# Cortex_M33 register map
Vendor: ARM Ltd.; File version: 1.3
CPU: CM33 r0p0, little endian, MPU, no FPU, vendor SysTick, 8 interrupt priority bits
Registers are 32-bit, read-write, no defined reset value unless marked. A register's access mark holds for its fields unless they carry their own. Offsets are from the block's base; [hi:lo] are bit positions; {n}, {i} and the like mark numbered series; 'fields as' and 'values as' point back to an identical list.

## ICB — Interrupt Control Registers
Base 0xE000E004
0x00 ICTR ro
  [3:0] INTLINESNUM
0x04 ACTLR
0x08 CPPWR
  [23] SUS11, [22] SU11, [21] SUS10, [20] SU10, [n] SUS{n} (n=0..7), [n] SU{n} (n=0..7)

## MPU — Memory protection Unit Control Registers
Base 0xE000ED90
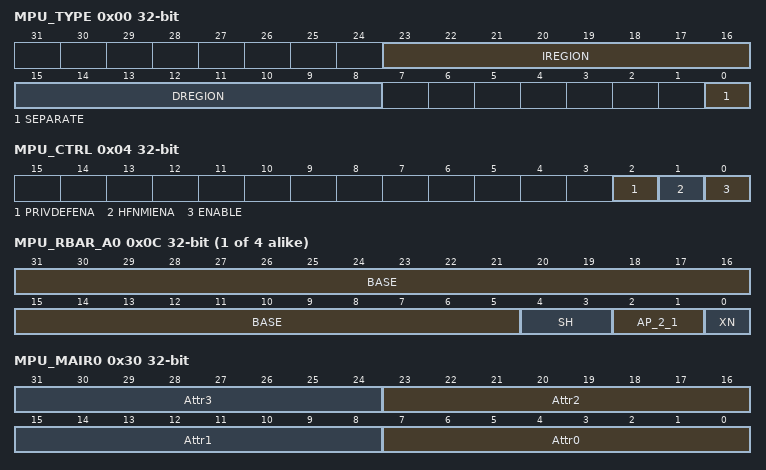
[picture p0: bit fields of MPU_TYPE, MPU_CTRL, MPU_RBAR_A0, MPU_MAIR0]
0x00 MPU_TYPE ro — MPU Type Register S
  [23:16] IREGION
  [15:8] DREGION
  [0] SEPARATE
    0=Uniform; 1=Separate
0x04 MPU_CTRL — MPU Control Register S
  [2] PRIVDEFENA, [1] HFNMIENA, [0] ENABLE
0x08 MPU_RNR — MPU Region Number Register S
  [7:0] REGION
0x0C MPU_RBAR_A{i} (i=0..3) — MPU_RBAR_A{i}_S
  [31:5] BASE, [4:3] SH, [2:1] AP_2_1, [0] XN
0x30 MPU_MAIR0 — MPU_MAIR0_S
  [8n+7:8n] Attr{n} (n=0..3)
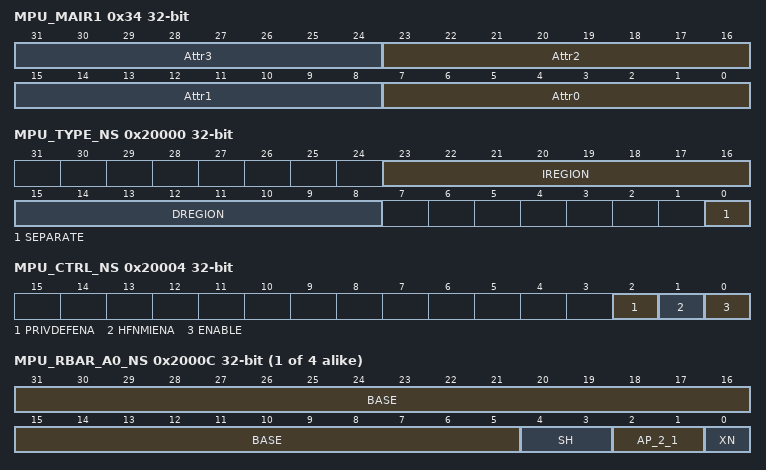
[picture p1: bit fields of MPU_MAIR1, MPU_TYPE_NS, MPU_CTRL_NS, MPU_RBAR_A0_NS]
0x34 MPU_MAIR1 — MPU_MAIR1_S
  [8n+7:8n] Attr{n} (n=0..3)
0x20000 MPU_TYPE_NS ro — MPU Type Register NS
  fields as MPU_TYPE
0x20004 MPU_CTRL_NS — MPU Control Register NS
  [2] PRIVDEFENA, [1] HFNMIENA, [0] ENABLE
0x20008 MPU_RNR_NS — MPU Region Number Register NS
  [7:0] REGION
0x2000C MPU_RBAR_A{i}_NS (i=0..3)
  [31:5] BASE, [4:3] SH, [2:1] AP_2_1, [0] XN
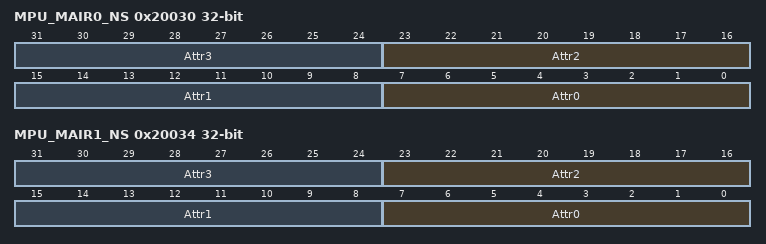
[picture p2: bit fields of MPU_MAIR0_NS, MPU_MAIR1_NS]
0x20030 MPU_MAIR0_NS
  [8n+7:8n] Attr{n} (n=0..3)
0x20034 MPU_MAIR1_NS
  [8n+7:8n] Attr{n} (n=0..3)

## NVIC — Nested Vectored Interrupt Controller registers
Base 0xE000E004
0x00 ICTR ro — Interrupt Controller Type Register
  [3:0] INTLINESNUM
{0xFC+4i} NVIC_ISER{i} reset 0x0 (i=0..15) — Interrupt Set-Enable Register
  [31:0] SETENA
{0x17C+4i} NVIC_ICER{i} reset 0x0 (i=0..15) — Interrupt Clear-Enable Register
  [31:0] CLRENA
{0x1FC+4i} NVIC_ISPR{i} reset 0x0 (i=0..15) — Interrupt Set-Pending Register
  [31:0] SETPEND
{0x27C+4i} NVIC_ICPR{i} reset 0x0 (i=0..15) — Interrupt Clear-Pending Register
  [31:0] CLRPEND
{0x2FC+4i} NVIC_IABR{i} reset 0x0 (i=0..15) — Interrupt Active Bit Register
  [31:0] ACTIVE
{0x37C+4i} ITNS{i} reset 0x0 (i=0..15) — Interrupt Target Non-secure Registers
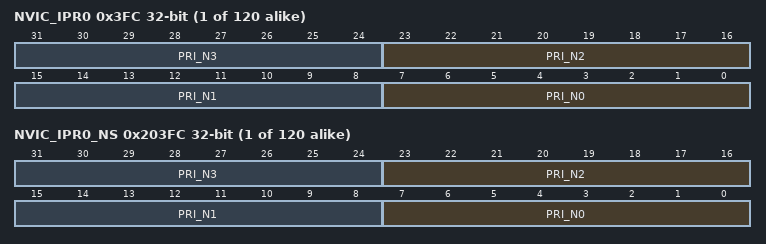
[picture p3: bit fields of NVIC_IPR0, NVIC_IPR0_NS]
{0x3FC+4i} NVIC_IPR{i} (i=0..119)
  [8n+7:8n] PRI_N{n} (n=0..3)
0x20000 ICTR_NS ro — Interrupt Controller Type Register NS
  [3:0] INTLINESNUM
{0x200FC+4i} NVIC_ISER{i}_NS reset 0x0 (i=0..15) — Interrupt Set-Enable Register
  [31:0] SETENA
{0x2017C+4i} NVIC_ICER{i}_NS reset 0x0 (i=0..15) — Interrupt Clear-Enable Register
  [31:0] CLRENA
{0x201FC+4i} NVIC_ISPR{i}_NS reset 0x0 (i=0..15) — Interrupt Set-Pending Register
  [31:0] SETPEND
{0x2027C+4i} NVIC_ICPR{i}_NS reset 0x0 (i=0..15) — Interrupt Clear-Pending Register
  [31:0] CLRPEND
{0x202FC+4i} NVIC_IABR{i}_NS reset 0x0 (i=0..15) — Interrupt Active Bit Register
  [31:0] ACTIVE
{0x203FC+4i} NVIC_IPR{i}_NS (i=0..119)
  [8n+7:8n] PRI_N{n} (n=0..3)

## SAU — Security Attribute Unit
Base 0xE000EDD0
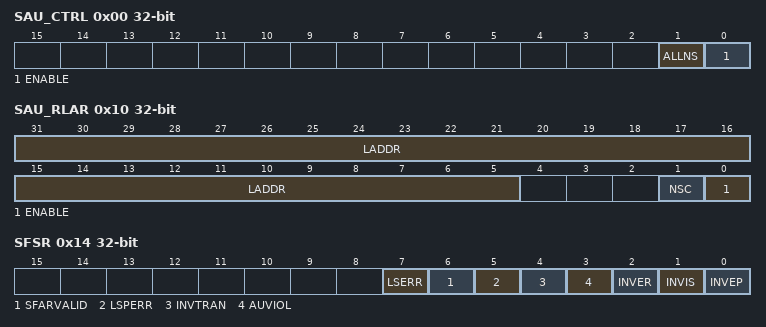
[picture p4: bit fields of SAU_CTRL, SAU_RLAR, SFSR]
0x00 SAU_CTRL
  [1] ALLNS, [0] ENABLE
0x04 SAU_TYPE ro
  [7:0] SREGION
0x08 SAU_RNR
  [7:0] REGION
0x0C SAU_RBAR
  [31:5] BADDR
0x10 SAU_RLAR
  [31:5] LADDR, [1] NSC, [0] ENABLE
0x14 SFSR
  [7] LSERR, [6] SFARVALID, [5] LSPERR, [4] INVTRAN, [3] AUVIOL, [2] INVER, [1] INVIS, [0] INVEP
0x18 SFAR
  [31:0] ADDRESS

## SIG — Software Interrupt Control
Base 0xE000EF00
0x00 STIR wo
  [8:0] INTID

## SYST — SysTick Control Registers
Base 0xE000E010
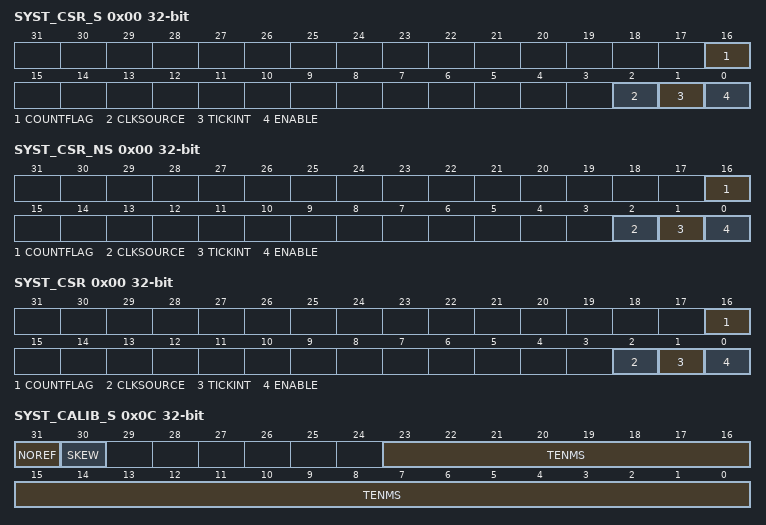
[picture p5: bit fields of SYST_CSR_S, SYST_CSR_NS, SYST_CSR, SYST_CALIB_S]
0x00 SYST_CSR_S
  [16] COUNTFLAG, [2] CLKSOURCE, [1] TICKINT, [0] ENABLE
0x00 SYST_CSR_NS
  [16] COUNTFLAG, [2] CLKSOURCE, [1] TICKINT, [0] ENABLE
0x00 SYST_CSR
  [16] COUNTFLAG, [2] CLKSOURCE, [1] TICKINT, [0] ENABLE
0x04 SYST_RVR_S
  [23:0] RELOAD
0x04 SYST_RVR_NS
  [23:0] RELOAD
0x04 SYST_RVR
  [23:0] RELOAD
0x08 SYST_CVR_S
  [23:0] CURRENT
0x08 SYST_CVR_NS
  [23:0] CURRENT
0x08 SYST_CVR
  [23:0] CURRENT
0x0C SYST_CALIB_S ro
  [31] NOREF, [30] SKEW, [23:0] TENMS
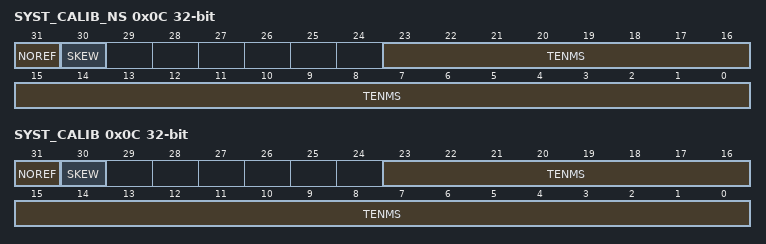
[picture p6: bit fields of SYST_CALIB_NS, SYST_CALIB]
0x0C SYST_CALIB_NS ro
  [31] NOREF, [30] SKEW, [23:0] TENMS
0x0C SYST_CALIB ro
  [31] NOREF, [30] SKEW, [23:0] TENMS
